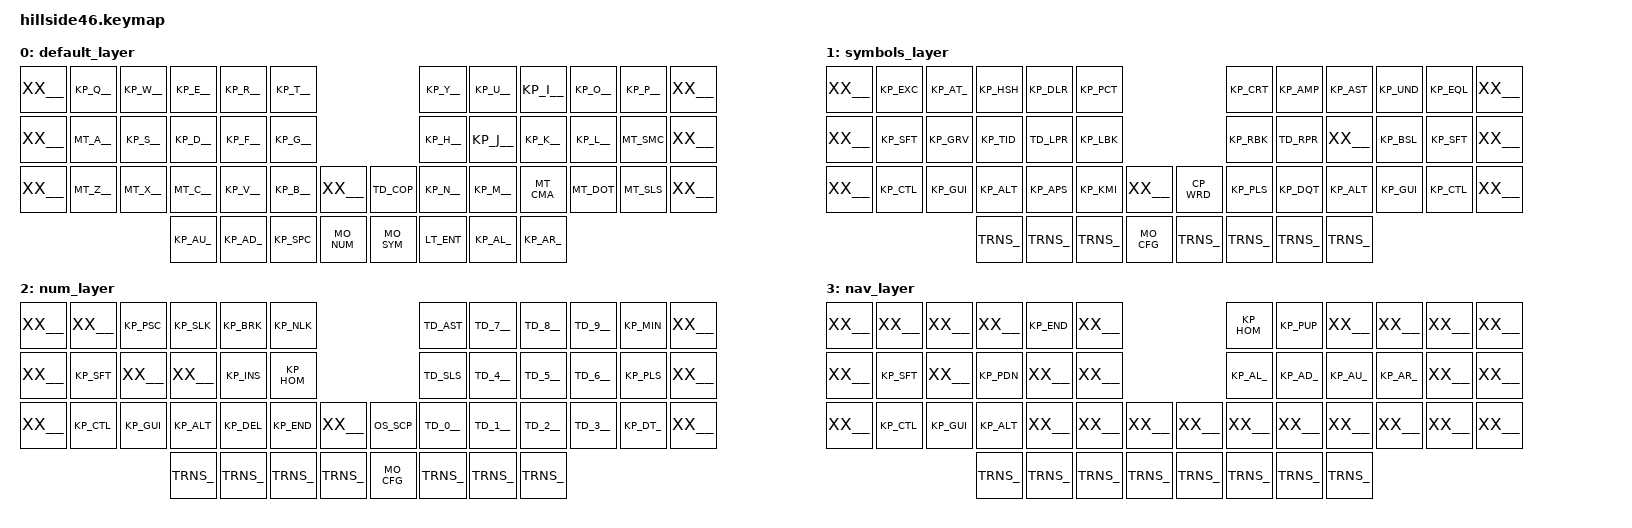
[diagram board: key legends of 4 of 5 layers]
/*
* Copyright (c) 2021-2022 The ZMK Contributors
*
* SPDX-License-Identifier: MIT
*/

#include <behaviors.dtsi>

#include "../custom/custom.dtsi"

#include <dt-bindings/zmk/bt.h>
#include <dt-bindings/zmk/ext_power.h>
#include <dt-bindings/zmk/keys.h>
#include <dt-bindings/zmk/outputs.h>

/ {
  keymap {
    compatible = "zmk,keymap";

    default_layer {
      bindings = <
        __XX__  KP_Q__  KP_W__  KP_E__  KP_R__  KP_T__                    KP_Y__  KP_U__  KP_I__  KP_O__  KP_P__  __XX__
        __XX__  MT_A__  KP_S__  KP_D__  KP_F__  KP_G__                    KP_H__  KP_J__  KP_K__  KP_L__  MT_SMC  __XX__
        __XX__  MT_Z__  MT_X__  MT_C__  KP_V__  KP_B__  __XX__    TD_COP  KP_N__  KP_M__  MT_CMA  MT_DOT  MT_SLS  __XX__
                                KP_AU_  KP_AD_  KP_SPC  MO_NUM    MO_SYM  LT_ENT  KP_AL_  KP_AR_
      >;

      sensor-bindings = <&inc_dec_kp LC(LG(RIGHT)) LC(LG(LEFT))>;
    };

    symbols_layer {
      bindings = <
        __XX__  KP_EXC  KP_AT_  KP_HSH  KP_DLR  KP_PCT                    KP_CRT  KP_AMP  KP_AST  KP_UND  KP_EQL  __XX__
        __XX__  KP_SFT  KP_GRV  KP_TID  TD_LPR  KP_LBK                    KP_RBK  TD_RPR  __XX__  KP_BSL  KP_SFT  __XX__
        __XX__  KP_CTL  KP_GUI  KP_ALT  KP_APS  KP_KMI  __XX__    CP_WRD  KP_PLS  KP_DQT  KP_ALT  KP_GUI  KP_CTL  __XX__
                                _TRNS_  _TRNS_  _TRNS_  MO_CFG    _TRNS_  _TRNS_  _TRNS_  _TRNS_
      >;

      sensor-bindings = <&inc_dec_kp LC(Z) LC(LS(Z))>;
    };

    num_layer {
      bindings = <
        __XX__  __XX__  KP_PSC  KP_SLK  KP_BRK  KP_NLK                    TD_AST  TD_7__  TD_8__  TD_9__  KP_MIN  __XX__
        __XX__  KP_SFT  __XX__  __XX__  KP_INS  KP_HOM                    TD_SLS  TD_4__  TD_5__  TD_6__  KP_PLS  __XX__
        __XX__  KP_CTL  KP_GUI  KP_ALT  KP_DEL  KP_END  __XX__    OS_SCP  TD_0__  TD_1__  TD_2__  TD_3__  KP_DT_  __XX__
                                _TRNS_  _TRNS_  _TRNS_  _TRNS_    MO_CFG  _TRNS_  _TRNS_  _TRNS_
      >;

      sensor-bindings = <&inc_dec_kp LC(TAB) LC(LS(TAB))>;
    };

    nav_layer {
      bindings = <
        __XX__  __XX__  __XX__  __XX__  KP_END  __XX__                    KP_HOM  KP_PUP  __XX__  __XX__  __XX__  __XX__
        __XX__  KP_SFT  __XX__  KP_PDN  __XX__  __XX__                    KP_AL_  KP_AD_  KP_AU_  KP_AR_  __XX__  __XX__
        __XX__  KP_CTL  KP_GUI  KP_ALT  __XX__  __XX__  __XX__    __XX__  __XX__  __XX__  __XX__  __XX__  __XX__  __XX__
                                _TRNS_  _TRNS_  _TRNS_  _TRNS_    _TRNS_  _TRNS_  _TRNS_  _TRNS_
      >;

      sensor-bindings = <&inc_dec_mwh SCROLL_DOWN SCROLL_UP>;
    };

    config_layer {
      bindings = <
        __XX__  __XX__  __XX__  __XX__  __XX__  BT_CLA                    BT_SE0  BT_SE1  BT_SE2  BT_SE3  BT_SE4  __XX__
        __XX__  __XX__  __XX__  __XX__  __XX__  __XX__                    __XX__  __XX__  __XX__  __XX__  __XX__  __XX__
        __XX__  __XX__  __XX__  __XX__  __XX__  __XX__  __XX__    __XX__  __XX__  __XX__  __XX__  __XX__  __XX__  __XX__
                                __XX__  __XX__  __XX__  _TRNS_    _TRNS_  __XX__  __XX__  __XX__  __XX__  __XX__  __XX__
      >;

      sensor-bindings = <&inc_dec_kp C_VOL_UP C_VOL_DN>;
    };

  };
};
